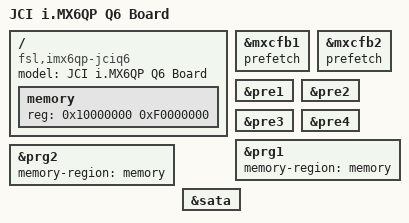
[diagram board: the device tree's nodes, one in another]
/*
 * Copyright 2012=2015 Freescale Semiconductor, Inc.
 * Copyright 2011 Linaro Ltd.
 *
 * The code contained herein is licensed under the GNU General Public
 * License. You may obtain a copy of the GNU General Public License
 * Version 2 or later at the following locations:
 *
 * http://www.opensource.org/licenses/gpl-license.html
 * http://www.gnu.org/copyleft/gpl.html
 */

/dts-v1/;

// includes non-QP .dtsi first
#include "imx6q-core-jciq6.dtsi"
#include "imx6qdl-jciq6.dtsi"
#include "imx6qp.dtsi"

/ {
	model = "JCI i.MX6QP Q6 Board";
	compatible = "fsl,imx6qp-jciq6", "fsl,imx6q";

	memory: memory {
		reg = <0x10000000 0xF0000000>;	/* reg = 0x10000000 base addr, 0xF0000000 size = 4GB */
	};
};

&mxcfb1 {
	prefetch;
};

&mxcfb2 {
	prefetch;
};

&pre1 {
	status = "okay";
};

&pre2 {
	status = "okay";
};

&pre3 {
	status = "okay";
};

&pre4 {
	status = "okay";
};

&prg1 {
	memory-region = <&memory>;
	status = "okay";
};

&prg2 {
	memory-region = <&memory>;
	status = "okay";
};

&sata {
	status = "okay";
};

